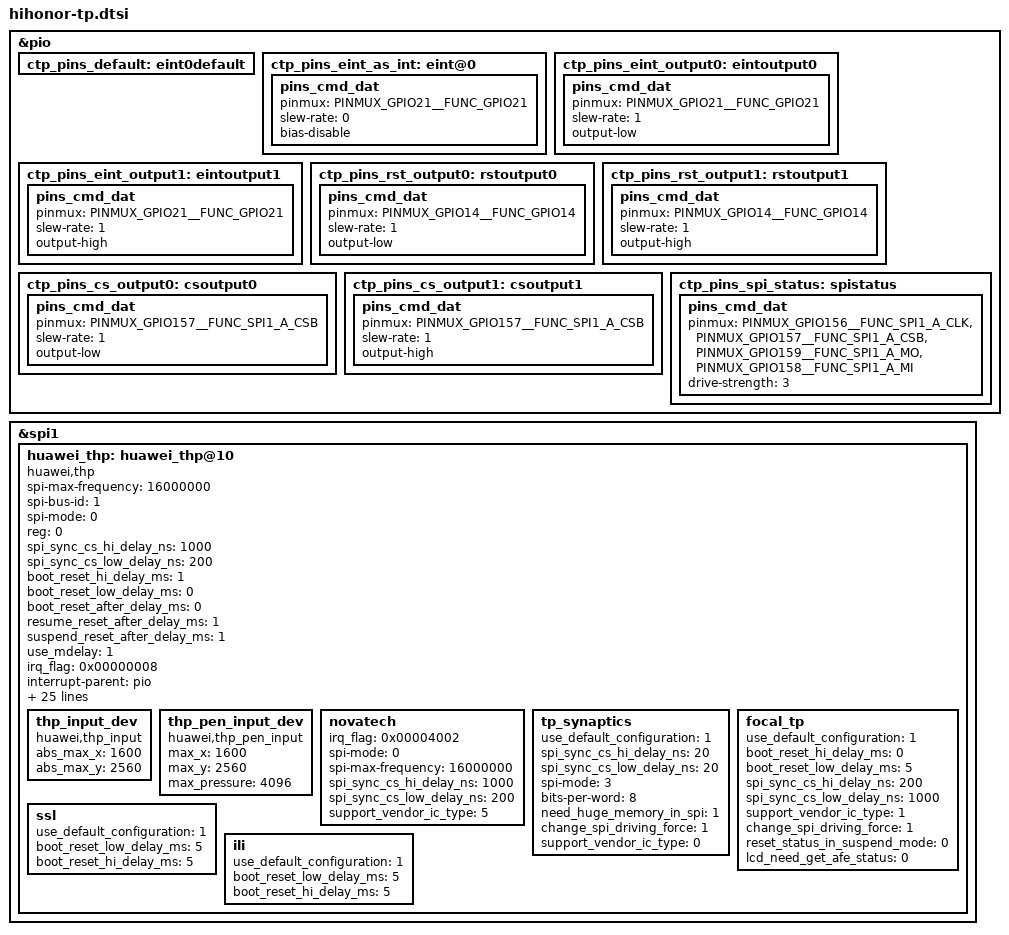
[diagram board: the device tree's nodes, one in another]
&pio {
	ctp_pins_default: eint0default {
	};
	ctp_pins_eint_as_int: eint@0 {
		pins_cmd_dat {
			pinmux = <PINMUX_GPIO21__FUNC_GPIO21>;
			slew-rate = <0>;
			bias-disable;
		};
	};
	ctp_pins_eint_output0: eintoutput0 {
		pins_cmd_dat {
			pinmux = <PINMUX_GPIO21__FUNC_GPIO21>;
			slew-rate = <1>;
			output-low;
		};
	};
	ctp_pins_eint_output1: eintoutput1 {
		pins_cmd_dat {
			pinmux = <PINMUX_GPIO21__FUNC_GPIO21>;
			slew-rate = <1>;
			output-high;
		};
	};
	ctp_pins_rst_output0: rstoutput0 {
		pins_cmd_dat {
			pinmux = <PINMUX_GPIO14__FUNC_GPIO14>;
			slew-rate = <1>;
			output-low;
		};
	};
	ctp_pins_rst_output1: rstoutput1 {
		pins_cmd_dat {
			pinmux = <PINMUX_GPIO14__FUNC_GPIO14>;
			slew-rate = <1>;
			output-high;
		};
	};

	ctp_pins_cs_output0: csoutput0 {
		pins_cmd_dat {
			pinmux = <PINMUX_GPIO157__FUNC_SPI1_A_CSB>;
			slew-rate = <1>;
			output-low;
		};
	};
	ctp_pins_cs_output1: csoutput1 {
		pins_cmd_dat {
			pinmux = <PINMUX_GPIO157__FUNC_SPI1_A_CSB>;
			slew-rate = <1>;
			output-high;
		};
	};
	ctp_pins_spi_status: spistatus {
		pins_cmd_dat {
			pinmux = <PINMUX_GPIO156__FUNC_SPI1_A_CLK>,
				 <PINMUX_GPIO157__FUNC_SPI1_A_CSB>,
				 <PINMUX_GPIO159__FUNC_SPI1_A_MO>,
				 <PINMUX_GPIO158__FUNC_SPI1_A_MI>;
			drive-strength = <3>;
		};
	};
};

&spi1 {
	status = "ok";
	huawei_thp: huawei_thp@10 {
		compatible = "huawei,thp";
		/* SPI Config */
		spi-max-frequency = <16000000>;
		spi-bus-id = <1>;
		spi-mode = <0>;
		reg = <0>;
		spi_sync_cs_hi_delay_ns = <1000>;
		spi_sync_cs_low_delay_ns = <200>;
		/* Timing */
		boot_reset_hi_delay_ms = <1>;
		boot_reset_low_delay_ms = <0>;
		boot_reset_after_delay_ms = <0>;
		resume_reset_after_delay_ms = <1>;
		suspend_reset_after_delay_ms = <1>;
		use_mdelay = <1>;
		/* GPIO Config */
		irq_flag = <0x00000008>;
		interrupt-parent = <&pio>;
		interrupts = <21 IRQ_TYPE_EDGE_FALLING 0 0>;
		/* PinCtrl Config */
		support_pinctrl = <1>;
		pinctrl-names = "default", "idle", "state_eint_as_int", "state_rst_output0",
			"state_rst_output1", "state_cs_output0", "state_cs_output1", "state_spi_status";
		pinctrl-0 = <&ctp_pins_rst_output1 &ctp_pins_cs_output1>;
		pinctrl-1 = <&ctp_pins_rst_output0 &ctp_pins_cs_output0>;
		pinctrl-2 = <&ctp_pins_eint_as_int>;
		pinctrl-3 = <&ctp_pins_rst_output0>;
		pinctrl-4 = <&ctp_pins_rst_output1>;
		pinctrl-5 = <&ctp_pins_cs_output0>;
		pinctrl-6 = <&ctp_pins_cs_output1>;
		pinctrl-7 = <&ctp_pins_spi_status>;
		/* Feature Config */
		pt_station_test = <1>;
		hide_product_info_en = <1>;
		support_no_cs_pinctrl_for_mtk = <1>;
		change_spi_driving_force = <1>;
		support_vendor_ic_type = <5>;
		wait_afe_screen_on_support = <1>;
		early_suspend_delay_ms = <200>;
		support_gesture_mode = <1>;
		lcd_gesture_mode_support = <1>;
		support_b_protocol = <1>;
		supported_charger = <1>;
		pen_supported = <1>;
		pen_mt_enable_flag = <1>;
		/* Input Config */
		thp_input_dev {
			compatible = "huawei,thp_input";
			abs_max_x = <1600>;
			abs_max_y = <2560>;
		};
		/* Pen Input Config */
		thp_pen_input_dev {
			compatible = "huawei,thp_pen_input";
			max_x = <1600>;
			max_y = <2560>;
			max_pressure = <4096>;
		};
		novatech {
			irq_flag = <0x00004002>;
			spi-mode = <0>;
			spi-max-frequency = <16000000>;
			spi_sync_cs_hi_delay_ns = <1000>;
			spi_sync_cs_low_delay_ns = <200>;
			support_vendor_ic_type = <5>;
		};
		tp_synaptics {
			use_default_configuration = <1>;
			spi_sync_cs_hi_delay_ns = <20>;
			spi_sync_cs_low_delay_ns = <20>;
			spi-mode = <3>;
			bits-per-word = <8>;
			need_huge_memory_in_spi = <1>;
			change_spi_driving_force = <1>;
			support_vendor_ic_type = <0>;
		};
		focal_tp {
			use_default_configuration = <1>;
			boot_reset_hi_delay_ms = <0>;
			boot_reset_low_delay_ms = <5>;
			spi_sync_cs_hi_delay_ns = <200>;
			spi_sync_cs_low_delay_ns = <1000>;
			support_vendor_ic_type = <1>;
			change_spi_driving_force = <1>;
			reset_status_in_suspend_mode = <0>;
			lcd_need_get_afe_status = <0>;
		};
		ssl {
			use_default_configuration = <1>;
			boot_reset_low_delay_ms = <5>;
			boot_reset_hi_delay_ms = <5>;
		};
		ili {
			use_default_configuration = <1>;
			boot_reset_low_delay_ms = <5>;
			boot_reset_hi_delay_ms = <5>;
		};
	};
};
